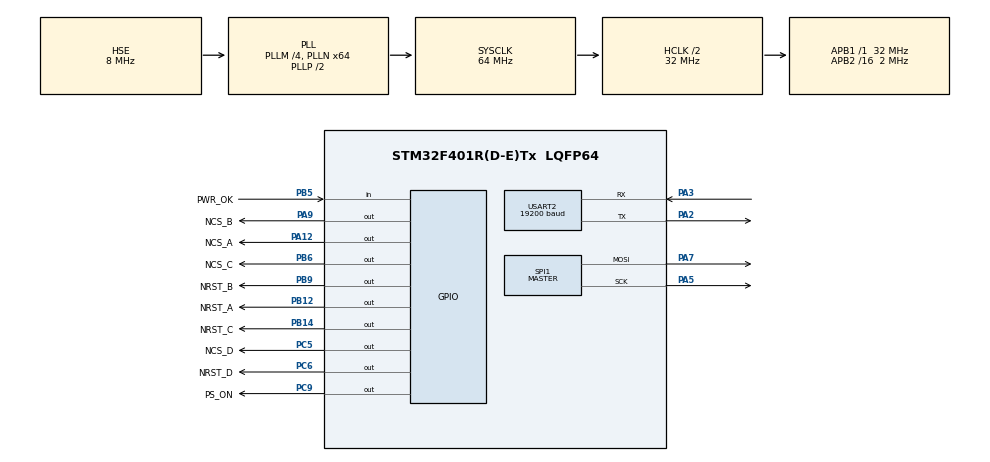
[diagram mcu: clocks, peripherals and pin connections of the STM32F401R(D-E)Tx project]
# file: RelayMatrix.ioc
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Dma.Request0=USART2_RX
Dma.USART2_RX.0.Direction=DMA_PERIPH_TO_MEMORY
Dma.USART2_RX.0.FIFOMode=DMA_FIFOMODE_DISABLE
Dma.USART2_RX.0.Instance=DMA1_Stream5
Dma.USART2_RX.0.MemDataAlignment=DMA_MDATAALIGN_BYTE
Dma.USART2_RX.0.MemInc=DMA_MINC_ENABLE
Dma.USART2_RX.0.Mode=DMA_NORMAL
Dma.USART2_RX.0.PeriphDataAlignment=DMA_PDATAALIGN_BYTE
Dma.USART2_RX.0.PeriphInc=DMA_PINC_DISABLE
Dma.USART2_RX.0.Priority=DMA_PRIORITY_HIGH
Mcu.Family=STM32F4
Mcu.Name=STM32F401R(D-E)Tx
Mcu.Package=LQFP64
NVIC.DMA1_Stream5_IRQn=true\:0\:0\:false\:false\:true\:false\:true\:true
NVIC.PriorityGroup=NVIC_PRIORITYGROUP_4
NVIC.SPI1_IRQn=true\:0\:0\:false\:false\:true\:true\:true\:true
NVIC.USART2_IRQn=true\:0\:0\:false\:false\:true\:true\:true\:true
PA12.GPIO_Label=NCS_A
PA12.GPIO_ModeDefaultOutputPP=GPIO_MODE_OUTPUT_OD
PA12.GPIO_PuPd=GPIO_NOPULL
PA12.PinState=GPIO_PIN_SET
PA12.Signal=GPIO_Output
PA2.Mode=Asynchronous
PA2.Signal=USART2_TX
PA3.Mode=Asynchronous
PA3.Signal=USART2_RX
PA5.Mode=TX_Only_Simplex_Unidirect_Master
PA5.Signal=SPI1_SCK
PA7.Mode=TX_Only_Simplex_Unidirect_Master
PA7.Signal=SPI1_MOSI
PA9.GPIO_Label=NCS_B
PA9.GPIO_ModeDefaultOutputPP=GPIO_MODE_OUTPUT_OD
PA9.GPIO_PuPd=GPIO_NOPULL
PA9.PinState=GPIO_PIN_SET
PA9.Signal=GPIO_Output
PB12.GPIO_Label=NRST_A
PB12.GPIO_ModeDefaultOutputPP=GPIO_MODE_OUTPUT_OD
PB12.GPIO_PuPd=GPIO_NOPULL
PB12.PinState=GPIO_PIN_SET
PB12.Signal=GPIO_Output
PB14.GPIO_Label=NRST_C
PB14.GPIO_ModeDefaultOutputPP=GPIO_MODE_OUTPUT_OD
PB14.GPIO_PuPd=GPIO_NOPULL
PB14.PinState=GPIO_PIN_SET
PB14.Signal=GPIO_Output
PB5.GPIO_Label=PWR_OK
PB5.Signal=GPIO_Input
PB6.GPIO_Label=NCS_C
PB6.GPIO_ModeDefaultOutputPP=GPIO_MODE_OUTPUT_OD
PB6.GPIO_PuPd=GPIO_NOPULL
PB6.PinState=GPIO_PIN_SET
PB6.Signal=GPIO_Output
PB9.GPIO_Label=NRST_B
PB9.GPIO_ModeDefaultOutputPP=GPIO_MODE_OUTPUT_OD
PB9.GPIO_PuPd=GPIO_NOPULL
PB9.PinState=GPIO_PIN_SET
PB9.Signal=GPIO_Output
PC5.GPIO_Label=NCS_D
PC5.GPIO_ModeDefaultOutputPP=GPIO_MODE_OUTPUT_OD
PC5.GPIO_PuPd=GPIO_NOPULL
PC5.PinState=GPIO_PIN_SET
PC5.Signal=GPIO_Output
PC6.GPIO_Label=NRST_D
PC6.GPIO_ModeDefaultOutputPP=GPIO_MODE_OUTPUT_OD
PC6.GPIO_PuPd=GPIO_NOPULL
PC6.PinState=GPIO_PIN_SET
PC6.Signal=GPIO_Output
PC9.GPIO_Label=PS_ON
PC9.PinState=GPIO_PIN_SET
PC9.Signal=GPIO_Output
PH0\ -\ OSC_IN.Mode=HSE-External-Oscillator
PH0\ -\ OSC_IN.Signal=RCC_OSC_IN
PH1\ -\ OSC_OUT.Mode=HSE-External-Oscillator
PH1\ -\ OSC_OUT.Signal=RCC_OSC_OUT
ProjectManager.HeapSize=0x200
ProjectManager.StackSize=0x400
ProjectManager.TargetToolchain=CMake
RCC.48MHZClocksFreq_Value=32000000
RCC.AHBCLKDivider=RCC_SYSCLK_DIV2
RCC.AHBFreq_Value=32000000
RCC.APB1Freq_Value=32000000
RCC.APB1TimFreq_Value=32000000
RCC.APB2CLKDivider=RCC_HCLK_DIV16
RCC.APB2Freq_Value=2000000
RCC.APB2TimFreq_Value=4000000
RCC.CortexFreq_Value=32000000
RCC.FLatency=FLASH_LATENCY_1
RCC.HCLKFreq_Value=32000000
RCC.HSE_VALUE=8000000
RCC.HSI_VALUE=16000000
RCC.LSE_VALUE=32768
RCC.PLLM=4
RCC.PLLN=64
RCC.PLLSourceVirtual=RCC_PLLSOURCE_HSE
RCC.SYSCLKFreq_VALUE=64000000
RCC.SYSCLKSource=RCC_SYSCLKSOURCE_PLLCLK
RCC.VCOOutputFreq_Value=128000000
SPI1.BaudRatePrescaler=SPI_BAUDRATEPRESCALER_2
SPI1.CLKPolarity=SPI_POLARITY_LOW
SPI1.Direction=SPI_DIRECTION_2LINES
SPI1.FirstBit=SPI_FIRSTBIT_MSB
SPI1.Mode=SPI_MODE_MASTER
SPI1.VirtualType=VM_MASTER
USART2.BaudRate=19200
USART2.VirtualMode=VM_ASYNC
VP_TIM3_VS_ClockSourceINT.Mode=Internal
board=custom

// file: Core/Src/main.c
/* USER CODE BEGIN Header */
/**
 ******************************************************************************
 * @file           : main.c
 * @brief          : Main program body
 ******************************************************************************
 * @attention
 *
 * Copyright (c) 2024 STMicroelectronics.
 * All rights reserved.
 *
 * This software is licensed under terms that can be found in the LICENSE file
 * in the root directory of this software component.
 * If no LICENSE file comes with this software, it is provided AS-IS.
 *
 ******************************************************************************
 */
/* USER CODE END Header */
#include "main.h"

/* USER CODE BEGIN Includes */
#include "fsm.h"
#include "config.h"
#include "queues.h"

#include "switch_commute.h"
/* USER CODE END Includes */

SPI_HandleTypeDef hspi1;

TIM_HandleTypeDef htim3;

UART_HandleTypeDef huart2;
DMA_HandleTypeDef hdma_usart2_rx;

void SystemClock_Config(void);
static void MX_GPIO_Init(void);
static void MX_DMA_Init(void);
static void MX_SPI1_Init(void);
static void MX_USART2_UART_Init(void);
static void MX_TIM3_Init(void);

/* USER CODE BEGIN 0 */
#include "queues.h"
/* USER CODE END 0 */

int main(void)
{

  /* MCU Configuration--------------------------------------------------------*/

  /* Reset of all peripherals, Initializes the Flash interface and the Systick. */
  HAL_Init();

  /* Configure the system clock */
  SystemClock_Config();

  /* Initialize all configured peripherals */
  MX_GPIO_Init();
  MX_DMA_Init();
  MX_SPI1_Init();
  MX_USART2_UART_Init();
  MX_TIM3_Init();
  /* USER CODE BEGIN 2 */
  HAL_TIM_Base_Start(&htim3);
  /* USER CODE END 2 */

  /* Infinite loop */
  /* USER CODE BEGIN WHILE */
  while (1)
  {
    state_handler(&huart2, &hspi1);
    /* USER CODE END WHILE */

  }
}

void SystemClock_Config(void)
{
  RCC_OscInitTypeDef RCC_OscInitStruct = {0};
  RCC_ClkInitTypeDef RCC_ClkInitStruct = {0};

  /** Configure the main internal regulator output voltage
  */
  __HAL_RCC_PWR_CLK_ENABLE();
  __HAL_PWR_VOLTAGESCALING_CONFIG(PWR_REGULATOR_VOLTAGE_SCALE2);

  /** Initializes the RCC Oscillators according to the specified parameters
  * in the RCC_OscInitTypeDef structure.
  */
  RCC_OscInitStruct.OscillatorType = RCC_OSCILLATORTYPE_HSE;
  RCC_OscInitStruct.HSEState = RCC_HSE_ON;
  RCC_OscInitStruct.PLL.PLLState = RCC_PLL_ON;
  RCC_OscInitStruct.PLL.PLLSource = RCC_PLLSOURCE_HSE;
  RCC_OscInitStruct.PLL.PLLM = 4;
  RCC_OscInitStruct.PLL.PLLN = 64;
  RCC_OscInitStruct.PLL.PLLP = RCC_PLLP_DIV2;
  RCC_OscInitStruct.PLL.PLLQ = 4;
  if (HAL_RCC_OscConfig(&RCC_OscInitStruct) != HAL_OK)
  {
    Error_Handler();
  }

  /** Initializes the CPU, AHB and APB buses clocks
  */
  RCC_ClkInitStruct.ClockType = RCC_CLOCKTYPE_HCLK|RCC_CLOCKTYPE_SYSCLK
                              |RCC_CLOCKTYPE_PCLK1|RCC_CLOCKTYPE_PCLK2;
  RCC_ClkInitStruct.SYSCLKSource = RCC_SYSCLKSOURCE_PLLCLK;
  RCC_ClkInitStruct.AHBCLKDivider = RCC_SYSCLK_DIV2;
  RCC_ClkInitStruct.APB1CLKDivider = RCC_HCLK_DIV1;
  RCC_ClkInitStruct.APB2CLKDivider = RCC_HCLK_DIV16;

  if (HAL_RCC_ClockConfig(&RCC_ClkInitStruct, FLASH_LATENCY_1) != HAL_OK)
  {
    Error_Handler();
  }
}

static void MX_SPI1_Init(void)
{

  /* SPI1 parameter configuration*/
  hspi1.Instance = SPI1;
  hspi1.Init.Mode = SPI_MODE_MASTER;
  hspi1.Init.Direction = SPI_DIRECTION_2LINES;
  hspi1.Init.DataSize = SPI_DATASIZE_8BIT;
  hspi1.Init.CLKPolarity = SPI_POLARITY_LOW;
  hspi1.Init.CLKPhase = SPI_PHASE_1EDGE;
  hspi1.Init.NSS = SPI_NSS_SOFT;
  hspi1.Init.BaudRatePrescaler = SPI_BAUDRATEPRESCALER_2;
  hspi1.Init.FirstBit = SPI_FIRSTBIT_MSB;
  hspi1.Init.TIMode = SPI_TIMODE_DISABLE;
  hspi1.Init.CRCCalculation = SPI_CRCCALCULATION_DISABLE;
  hspi1.Init.CRCPolynomial = 10;
  if (HAL_SPI_Init(&hspi1) != HAL_OK)
  {
    Error_Handler();
  }

}

static void MX_TIM3_Init(void)
{

  TIM_ClockConfigTypeDef sClockSourceConfig = {0};
  TIM_MasterConfigTypeDef sMasterConfig = {0};

  htim3.Instance = TIM3;
  htim3.Init.Prescaler = 0;
  htim3.Init.CounterMode = TIM_COUNTERMODE_UP;
  htim3.Init.Period = 65535;
  htim3.Init.ClockDivision = TIM_CLOCKDIVISION_DIV1;
  htim3.Init.AutoReloadPreload = TIM_AUTORELOAD_PRELOAD_DISABLE;
  if (HAL_TIM_Base_Init(&htim3) != HAL_OK)
  {
    Error_Handler();
  }
  sClockSourceConfig.ClockSource = TIM_CLOCKSOURCE_INTERNAL;
  if (HAL_TIM_ConfigClockSource(&htim3, &sClockSourceConfig) != HAL_OK)
  {
    Error_Handler();
  }
  sMasterConfig.MasterOutputTrigger = TIM_TRGO_RESET;
  sMasterConfig.MasterSlaveMode = TIM_MASTERSLAVEMODE_DISABLE;
  if (HAL_TIMEx_MasterConfigSynchronization(&htim3, &sMasterConfig) != HAL_OK)
  {
    Error_Handler();
  }

}

static void MX_USART2_UART_Init(void)
{

  huart2.Instance = USART2;
  huart2.Init.BaudRate = 19200;
  huart2.Init.WordLength = UART_WORDLENGTH_8B;
  huart2.Init.StopBits = UART_STOPBITS_1;
  huart2.Init.Parity = UART_PARITY_NONE;
  huart2.Init.Mode = UART_MODE_TX_RX;
  huart2.Init.HwFlowCtl = UART_HWCONTROL_NONE;
  huart2.Init.OverSampling = UART_OVERSAMPLING_16;
  if (HAL_UART_Init(&huart2) != HAL_OK)
  {
    Error_Handler();
  }

}

static void MX_DMA_Init(void)
{

  /* DMA controller clock enable */
  __HAL_RCC_DMA1_CLK_ENABLE();

  /* DMA interrupt init */
  /* DMA1_Stream5_IRQn interrupt configuration */
  HAL_NVIC_SetPriority(DMA1_Stream5_IRQn, 0, 0);
  HAL_NVIC_EnableIRQ(DMA1_Stream5_IRQn);

}

static void MX_GPIO_Init(void)
{
  GPIO_InitTypeDef GPIO_InitStruct = {0};

  /* GPIO Ports Clock Enable */
  __HAL_RCC_GPIOH_CLK_ENABLE();
  __HAL_RCC_GPIOA_CLK_ENABLE();
  __HAL_RCC_GPIOC_CLK_ENABLE();
  __HAL_RCC_GPIOB_CLK_ENABLE();

  /*Configure GPIO pin Output Level */
  HAL_GPIO_WritePin(GPIOC, NCS_D_Pin|NRST_D_Pin|PS_ON_Pin, GPIO_PIN_SET);

  /*Configure GPIO pin Output Level */
  HAL_GPIO_WritePin(GPIOB, NRST_A_Pin|NRST_C_Pin|NCS_C_Pin|NRST_B_Pin, GPIO_PIN_SET);

  /*Configure GPIO pin Output Level */
  HAL_GPIO_WritePin(GPIOA, NCS_B_Pin|NCS_A_Pin, GPIO_PIN_SET);

  /*Configure GPIO pins : NCS_D_Pin NRST_D_Pin */
  GPIO_InitStruct.Pin = NCS_D_Pin|NRST_D_Pin;
  GPIO_InitStruct.Mode = GPIO_MODE_OUTPUT_OD;
  GPIO_InitStruct.Pull = GPIO_NOPULL;
  GPIO_InitStruct.Speed = GPIO_SPEED_FREQ_LOW;
  HAL_GPIO_Init(GPIOC, &GPIO_InitStruct);

  /*Configure GPIO pins : NRST_A_Pin NRST_C_Pin NCS_C_Pin NRST_B_Pin */
  GPIO_InitStruct.Pin = NRST_A_Pin|NRST_C_Pin|NCS_C_Pin|NRST_B_Pin;
  GPIO_InitStruct.Mode = GPIO_MODE_OUTPUT_OD;
  GPIO_InitStruct.Pull = GPIO_NOPULL;
  GPIO_InitStruct.Speed = GPIO_SPEED_FREQ_LOW;
  HAL_GPIO_Init(GPIOB, &GPIO_InitStruct);

  /*Configure GPIO pin : PS_ON_Pin */
  GPIO_InitStruct.Pin = PS_ON_Pin;
  GPIO_InitStruct.Mode = GPIO_MODE_OUTPUT_PP;
  GPIO_InitStruct.Pull = GPIO_NOPULL;
  GPIO_InitStruct.Speed = GPIO_SPEED_FREQ_LOW;
  HAL_GPIO_Init(PS_ON_GPIO_Port, &GPIO_InitStruct);

  /*Configure GPIO pins : NCS_B_Pin NCS_A_Pin */
  GPIO_InitStruct.Pin = NCS_B_Pin|NCS_A_Pin;
  GPIO_InitStruct.Mode = GPIO_MODE_OUTPUT_OD;
  GPIO_InitStruct.Pull = GPIO_NOPULL;
  GPIO_InitStruct.Speed = GPIO_SPEED_FREQ_LOW;
  HAL_GPIO_Init(GPIOA, &GPIO_InitStruct);

  /*Configure GPIO pin : PWR_OK_Pin */
  GPIO_InitStruct.Pin = PWR_OK_Pin;
  GPIO_InitStruct.Mode = GPIO_MODE_INPUT;
  GPIO_InitStruct.Pull = GPIO_NOPULL;
  HAL_GPIO_Init(PWR_OK_GPIO_Port, &GPIO_InitStruct);

}

void Error_Handler(void)
{
  __disable_irq();
  while (1)
  {
  }
}
